# PY32F001Bxx register map
Vendor: Puya; Series: PY32F0; File version: 1.0.0
CPU: CM0+ r0p1, little endian, no MPU, no FPU, 4 interrupt priority bits
Registers are 32-bit, read-write, reset 0x0 unless marked. A register's access mark holds for its fields unless they carry their own. Offsets are from the block's base; [hi:lo] are bit positions; {n}, {i} and the like mark numbered series.

## FLASH
Base 0x40022000
0x08 KEYR — Flash key register
  [31:0] KEY wo — Flash CR key
0x0C OPTKEYR — Option byte key register
  [31:0] OPTKEY wo — Flash Option key
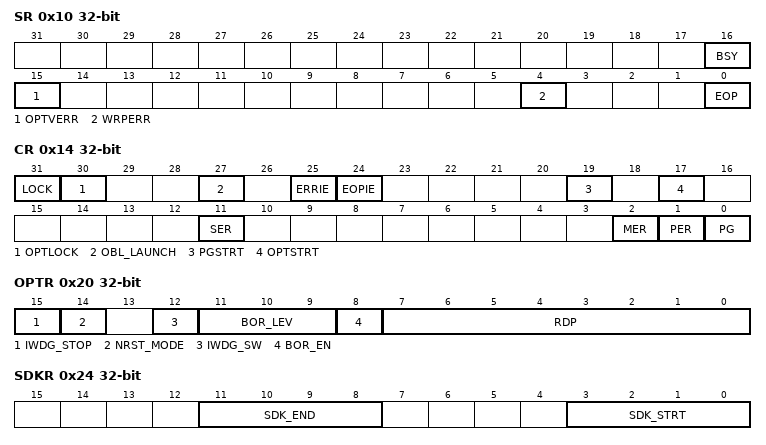
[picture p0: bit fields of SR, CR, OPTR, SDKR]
0x10 SR — Status register
  [16] BSY ro — Busy
  [15] OPTVERR — Option and trimming bits loading validity error
  [4] WRPERR — Write protection error
  [0] EOP — End of operation
0x14 CR — Flash control register
  [31] LOCK
  [30] OPTLOCK — Option Lock
  [27] OBL_LAUNCH — Force the option bytes loading
  [25] ERRIE — Error interrupt enable
  [24] EOPIE — End of operation interrupt enable
  [19] PGSTRT — Programming Start
  [17] OPTSTRT — Option bytes Programming Start
  [11] SER — Sector Erase
  [2] MER — Mass Erase
  [1] PER — Page Erase
  [0] PG — Page Program
0x20 OPTR — Flash option register
  [15] IWDG_STOP — IWDG Software Enable
  [14] NRST_MODE
  [12] IWDG_SW
  [11:9] BOR_LEV
  [8] BOR_EN
  [7:0] RDP — Read Protection
0x24 SDKR — Flash SDK address register
  [11:8] SDK_END, [3:0] SDK_STRT
0x2C WRPR — Flash WRP address register
  [15:0] WRP
0x90 STCR — Flash sleep time config register
  [0] SLEEP_EN — Sleep enable
0x100 TS0 — Flash TS0 register
  [7:0] TS0
0x104 TS1 — Flash TS1 register
  [7:0] TS1
0x108 TS2P — Flash TS2P register
  [7:0] TS2P
0x10C TPS3 — Flash TPS3 register
  [9:0] TPS3
0x110 TS3 — Flash TS3 register
  [7:0] TS3
0x114 ERTPE
  [15:0] ERTPE
0x11C PRGTPE — Flash PRGTPE register
  [15:0] PRGTPE
0x120 PRETPE — Flash PRETPE register
  [13:0] PRETPE

## GPIOA — General-purpose I/Os
Base 0x50000000
Same registers: GPIOB 0x50000400, GPIOC 0x50000800
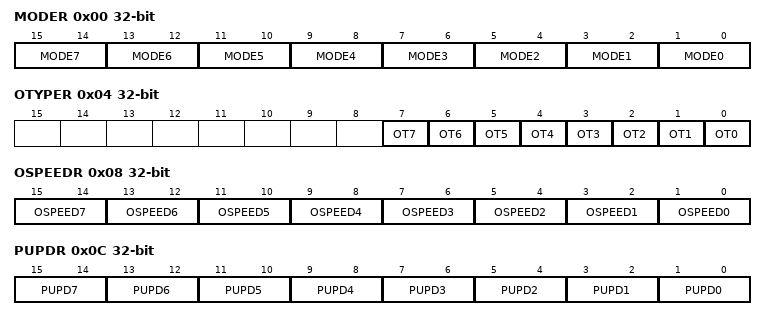
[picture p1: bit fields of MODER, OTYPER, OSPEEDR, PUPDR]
0x00 MODER — GPIO port mode register
  [2n+1:2n] MODE{n} (n=0..7) — Port x configuration bits (y = 0..15)
0x04 OTYPER — GPIO port output type register
  [n] OT{n} (n=0..7) — Port x configuration bits (y = 0..15)
0x08 OSPEEDR — GPIO port output speed register
  [2n+1:2n] OSPEED{n} (n=0..7) — Port x configuration bits (y = 0..15)
0x0C PUPDR — GPIO port pull-up/pull-down register
  [2n+1:2n] PUPD{n} (n=0..7) — Port x configuration bits (y = 0..15)
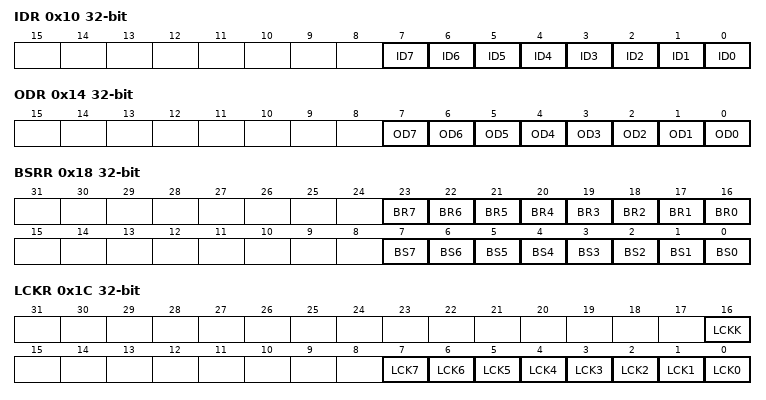
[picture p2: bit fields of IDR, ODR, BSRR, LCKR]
0x10 IDR — GPIO port input data register
  [n] ID{n} ro (n=0..7) — Port input data (y = 0..15)
0x14 ODR — GPIO port output data register
  [n] OD{n} (n=0..7) — Port output data (y = 0..15)
0x18 BSRR — GPIO port bit set/reset register
  [n+16] BR{n} (n=1..7) — Port x reset bit y (y = 0..15)
  [16] BR0 — Port x set bit y (y= 0..15)
  [n] BS{n} (n=0..7) — Port x set bit y (y= 0..15)
0x1C LCKR — GPIO port configuration lock register
  [16] LCKK — Port x lock bit y (y= 0..15)
  [n] LCK{n} (n=0..7) — Port x lock bit y (y= 0..15)
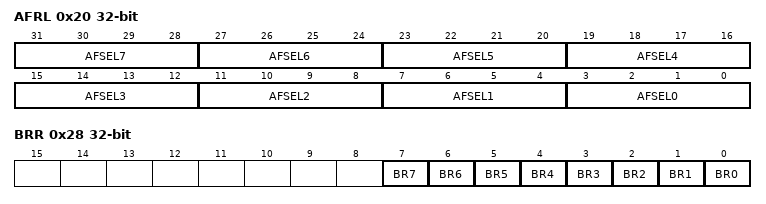
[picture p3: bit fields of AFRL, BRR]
0x20 AFRL — GPIO alternate function low register
  [4n+3:4n] AFSEL{n} (n=0..7) — Alternate function selection for port x bit y (y = 0..7)
0x28 BRR — port bit reset register
  [n] BR{n} (n=0..7) — Port Reset bit

## IWDG — Independent watchdog
Base 0x40003000
0x00 KR — Key register (IWDG_KR)
  [15:0] KEY — Key value
0x04 PR — Prescaler register (IWDG_PR)
  [2:0] PR — Prescaler divider
0x08 RLR — Reload register (IWDG_RLR)
  [11:0] RL — Watchdog counter reload value
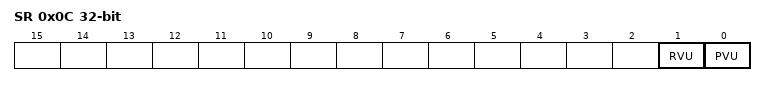
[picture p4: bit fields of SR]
0x0C SR — Status register (IWDG_SR)
  [1] RVU ro — Watchdog counter reload value update
  [0] PVU ro — Watchdog prescaler value update

## LPTIM1 — Low power timer
Base 0x40007C00
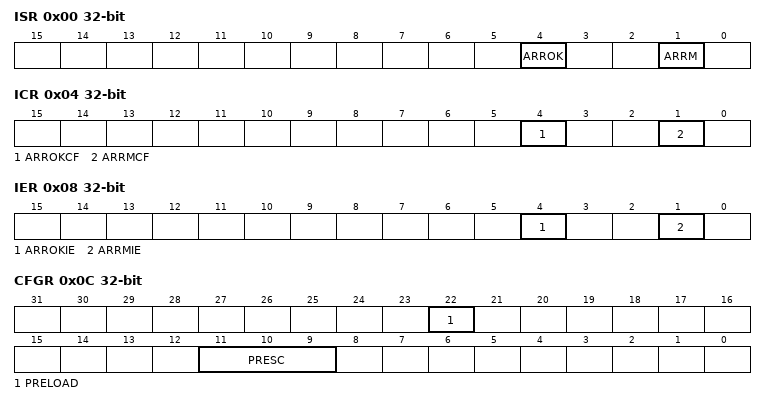
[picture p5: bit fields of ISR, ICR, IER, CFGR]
0x00 ISR — Interrupt and Status Register
  [4] ARROK ro — Autoreload match update OK
  [1] ARRM ro — Autoreload match
0x04 ICR — Interrupt Clear Register
  [4] ARROKCF — Autoreload match update OK Clear Flag
  [1] ARRMCF — Autoreload match Clear Flag
0x08 IER — Interrupt Enable Register
  [4] ARROKIE — Autoreload match update OK Interrupt Enable
  [1] ARRMIE — Autoreload matchInterrupt Enable
0x0C CFGR — Configuration Register
  [22] PRELOAD — Registers update mode
  [11:9] PRESC — Clock prescaler
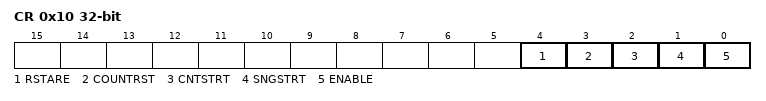
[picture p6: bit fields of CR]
0x10 CR — Control Register
  [4] RSTARE — Reset after read enable
  [3] COUNTRST — Reset counter
  [2] CNTSTRT
  [1] SNGSTRT — LPTIM start in single mode
  [0] ENABLE — LPTIM Enable
0x18 ARR — Autoreload Register
  [15:0] ARR — Auto reload value
0x1C CNT — Counter Register
  [15:0] CNT ro — Counter value
